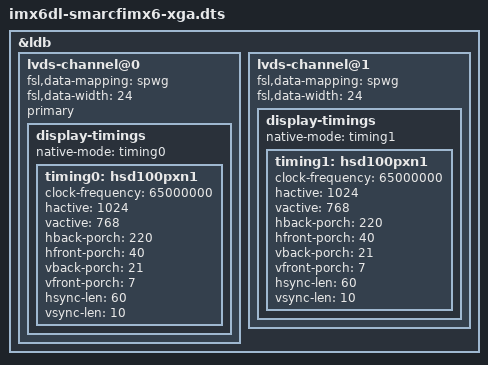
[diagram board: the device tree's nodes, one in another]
/*
 * Copyright (C) 2015 Embedian, Inc.
 *
 * This program is free software; you can redistribute it and/or modify
 * it under the terms of the GNU General Public License version 2 as
 * published by the Free Software Foundation.
 */

#include "imx6dl-smarcfimx6.dts"

&ldb {
        status = "okay";

        lvds-channel@0 {
                fsl,data-mapping = "spwg";
                fsl,data-width = <24>;
                primary;
                status = "okay";

                display-timings {
                        native-mode = <&timing0>;
                        timing0: hsd100pxn1 {
                                clock-frequency = <65000000>;
                                hactive = <1024>;
                                vactive = <768>;
                                hback-porch = <220>;
                                hfront-porch = <40>;
                                vback-porch = <21>;
                                vfront-porch = <7>;
                                hsync-len = <60>;
                                vsync-len = <10>;
                        };
                };
        };

        lvds-channel@1 {
                fsl,data-mapping = "spwg";
                fsl,data-width = <24>;
                status = "okay";

                display-timings {
                        native-mode = <&timing1>;
                        timing1: hsd100pxn1 {
                                clock-frequency = <65000000>;
                                hactive = <1024>;
                                vactive = <768>;
                                hback-porch = <220>;
                                hfront-porch = <40>;
                                vback-porch = <21>;
                                vfront-porch = <7>;
                                hsync-len = <60>;
                                vsync-len = <10>;
                        };
                };
        };
};
